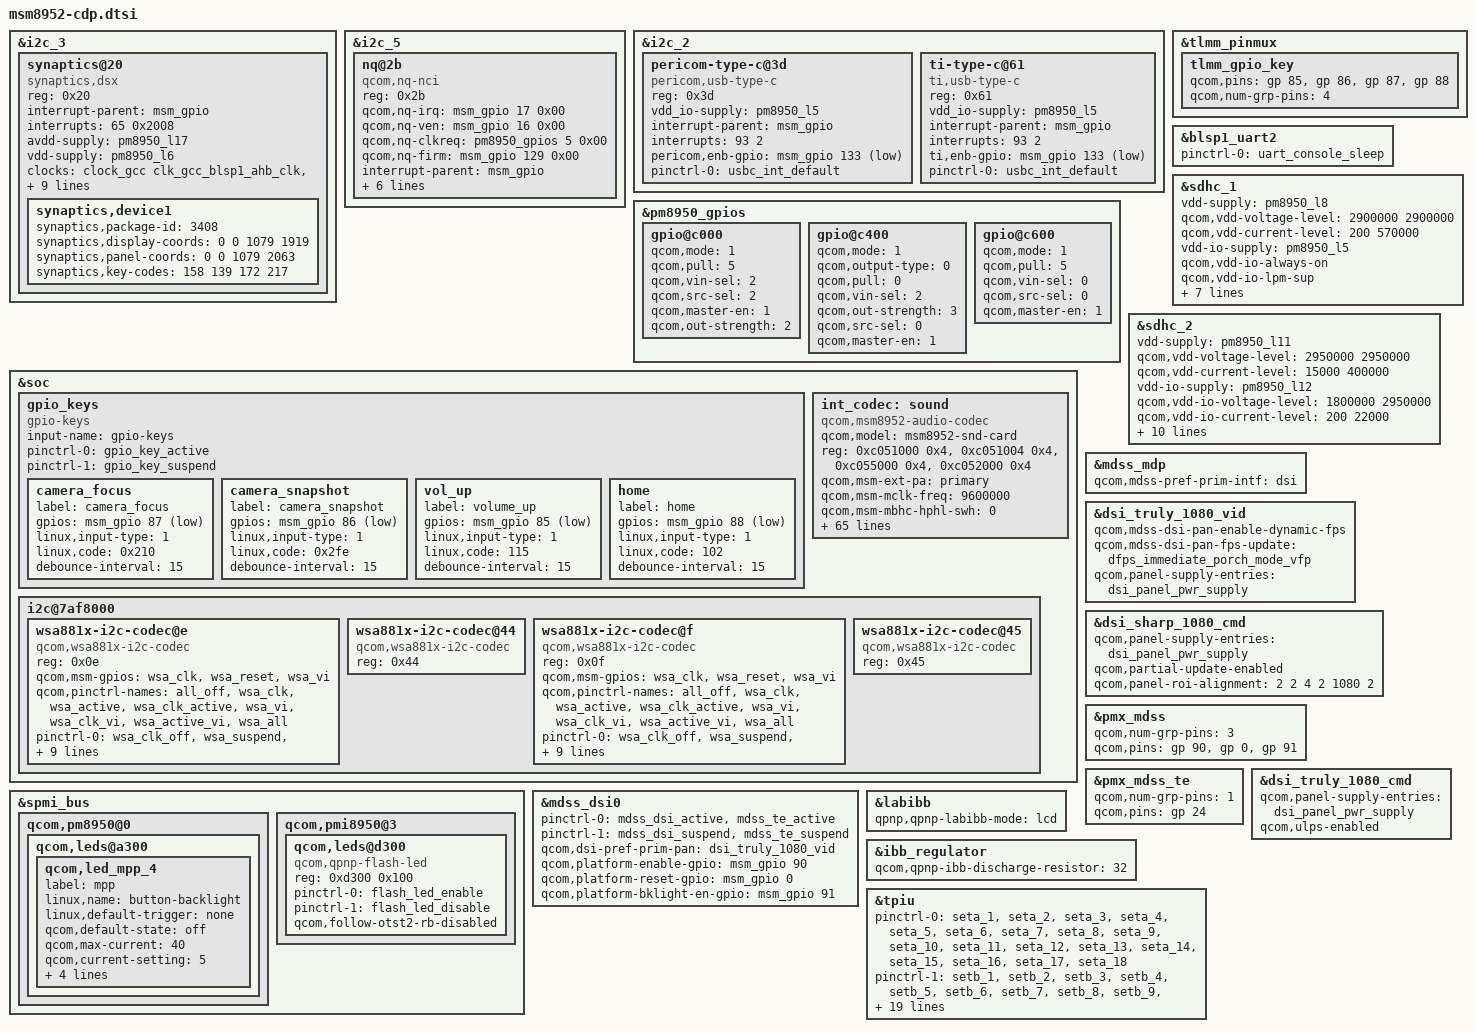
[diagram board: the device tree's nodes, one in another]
/*
 * Copyright (c) 2015, The Linux Foundation. All rights reserved.
 *
 * This program is free software; you can redistribute it and/or modify
 * it under the terms of the GNU General Public License version 2 and
 * only version 2 as published by the Free Software Foundation.
 *
 * This program is distributed in the hope that it will be useful,
 * but WITHOUT ANY WARRANTY; without even the implied warranty of
 * MERCHANTABILITY or FITNESS FOR A PARTICULAR PURPOSE.  See the
 * GNU General Public License for more details.
 */

#include "msm8952.dtsi"
#include "msm8952-pinctrl.dtsi"
#include "msm8952-camera-sensor-cdp.dtsi"

&i2c_3 { /* BLSP1 QUP3 */
	synaptics@20 {
		compatible = "synaptics,dsx";
		reg = <0x20>;
		interrupt-parent = <&msm_gpio>;
		interrupts = <65 0x2008>;
		avdd-supply = <&pm8950_l17>;
		vdd-supply = <&pm8950_l6>;
		clock-names = "iface_clk", "core_clk";
		clocks = <&clock_gcc clk_gcc_blsp1_ahb_clk>,
			<&clock_gcc clk_gcc_blsp1_qup3_i2c_apps_clk>;
		/* pins used by touchscreen */
		pinctrl-names = "pmx_ts_active","pmx_ts_suspend","pmx_ts_release";
		pinctrl-0 = <&ts_int_active &ts_reset_active>;
		pinctrl-1 = <&ts_int_suspend &ts_reset_suspend>;
		pinctrl-2 = <&ts_release>;
		synaptics,irq-gpio = <&msm_gpio 65 0x2008>;
		synaptics,reset-gpio = <&msm_gpio 64 0x0>;
		synaptics,disable-gpios;
		synaptics,detect-device;
		synaptics,bypass-packrat-id-check;
		synaptics,device1 {
			synaptics,package-id = <3408>;
			synaptics,display-coords = <0 0 1079 1919>;
			synaptics,panel-coords = <0 0 1079 2063>;
			synaptics,key-codes = <158 139 172 217>;
		};
	};
};

&i2c_5 { /* BLSP2 QUP1 */
	nq@2b {
		compatible = "qcom,nq-nci";
		reg = <0x2b>;
		qcom,nq-irq = <&msm_gpio 17 0x00>;
		qcom,nq-ven = <&msm_gpio 16 0x00>;
		qcom,nq-clkreq = <&pm8950_gpios 5 0x00>;
		qcom,nq-firm = <&msm_gpio 129 0x00>;
		interrupt-parent = <&msm_gpio>;
		qcom,clk-src = "BBCLK2";
		interrupts = <17 0>;
		interrupt-names = "nfc_irq";
		pinctrl-names = "nfc_active", "nfc_suspend";
		pinctrl-0 = <&nfc_int_active &nfc_disable_active>;
		pinctrl-1 = <&nfc_int_suspend &nfc_disable_suspend>;
		clocks = <&clock_gcc clk_bb_clk2_pin>;
		clock-names = "ref_clk";
	};
};

&i2c_2 {
	pericom-type-c@3d {
		compatible = "pericom,usb-type-c";
		reg = <0x3d>;
		vdd_io-supply = <&pm8950_l5>;
		interrupt-parent = <&msm_gpio>;
		interrupts = <93 2>;    /* MSM GPIO 93, TRIGGER_FALLING */
		pericom,enb-gpio = <&msm_gpio 133 0x1>;	/* active low ENB */
		pinctrl-names = "default";
		pinctrl-0 = <&usbc_int_default>;
	};

	ti-type-c@61 {
		compatible = "ti,usb-type-c";
		reg = <0x61>;
		vdd_io-supply = <&pm8950_l5>;
		interrupt-parent = <&msm_gpio>;
		interrupts = <93 2>;    /* MSM GPIO 93, TRIGGER_FALLING */
		ti,enb-gpio = <&msm_gpio 133 0x1>;	/* active low ENB */
		pinctrl-names = "default";
		pinctrl-0 = <&usbc_int_default>;
	};
};

&pm8950_gpios {
	gpio@c000 {
		status = "ok";
		qcom,mode = <1>;
		qcom,pull = <5>;
		qcom,vin-sel = <2>;
		qcom,src-sel = <2>;
		qcom,master-en = <1>;
		qcom,out-strength = <2>;
	};
	gpio@c400 {
		qcom,mode = <1>;
		qcom,output-type = <0>;
		qcom,pull = <0>;
		qcom,vin-sel = <2>;
		qcom,out-strength = <3>;
		qcom,src-sel = <0>;
		qcom,master-en = <1>;
		status = "okay";
	};
	gpio@c600 {
		status = "ok";
		qcom,mode = <1>;
		qcom,pull = <5>;
		qcom,vin-sel = <0>;
		qcom,src-sel = <0>;
		qcom,master-en = <1>;
	};
};

&soc {
	gpio_keys {
		compatible = "gpio-keys";
		input-name = "gpio-keys";
		pinctrl-names = "tlmm_gpio_key_active","tlmm_gpio_key_suspend";
		pinctrl-0 = <&gpio_key_active>;
		pinctrl-1 = <&gpio_key_suspend>;

		camera_focus {
			label = "camera_focus";
			gpios = <&msm_gpio 87 0x1>;
			linux,input-type = <1>;
			linux,code = <0x210>;
			debounce-interval = <15>;
		};

		camera_snapshot {
			label = "camera_snapshot";
			gpios = <&msm_gpio 86 0x1>;
			linux,input-type = <1>;
			linux,code = <0x2fe>;
			debounce-interval = <15>;
		};

		vol_up {
			label = "volume_up";
			gpios = <&msm_gpio 85 0x1>;
			linux,input-type = <1>;
			linux,code = <115>;
			debounce-interval = <15>;
		};

		home {
			label = "home";
			gpios = <&msm_gpio 88 0x1>;
			linux,input-type = <1>;
			linux,code = <102>;
			debounce-interval = <15>;
		};
	};

	int_codec: sound {
		compatible = "qcom,msm8952-audio-codec";
		qcom,model = "msm8952-snd-card";
		reg = <0xc051000 0x4>,
		      <0xc051004 0x4>,
		      <0xc055000 0x4>,
		      <0xc052000 0x4>;
		reg-names = "csr_gp_io_mux_mic_ctl",
			    "csr_gp_io_mux_spkr_ctl",
			    "csr_gp_io_lpaif_pri_pcm_pri_mode_muxsel",
			    "csr_gp_io_mux_quin_ctl";

		qcom,msm-ext-pa = "primary";
		qcom,msm-mclk-freq = <9600000>;
		qcom,msm-mbhc-hphl-swh = <0>;
		qcom,msm-mbhc-gnd-swh = <0>;
		qcom,msm-hs-micbias-type = "external";
		qcom,msm-micbias1-ext-cap;
		qcom,audio-routing =
			"RX_BIAS", "MCLK",
			"SPK_RX_BIAS", "MCLK",
			"INT_LDO_H", "MCLK",
			"MIC BIAS External", "Handset Mic",
			"MIC BIAS External2", "Headset Mic",
			"MIC BIAS External", "Secondary Mic",
			"AMIC1", "MIC BIAS External",
			"AMIC2", "MIC BIAS External2",
			"AMIC3", "MIC BIAS External",
			"WSA_SPK OUT", "VDD_WSA_SWITCH",
			"SpkrMono WSA_IN", "WSA_SPK OUT";
		qcom,msm-gpios =
			"pri_i2s",
			"us_eu_gpio";
		qcom,pinctrl-names =
			"all_off",
			"pri_i2s_act",
			"us_eu_gpio_act",
			"pri_i2s_us_eu_gpio_act";
		pinctrl-names =
			"all_off",
			"pri_i2s_act",
			"us_eu_gpio_act",
			"pri_i2s_us_eu_gpio_act";
		pinctrl-0 = <&cdc_pdm_lines_sus &cdc_pdm_lines_2_sus &cross_conn_det_sus>;
		pinctrl-1 = <&cdc_pdm_lines_act &cdc_pdm_lines_2_act &cross_conn_det_sus>;
		pinctrl-2 = <&cdc_pdm_lines_sus &cdc_pdm_lines_2_sus &cross_conn_det_act>;
		pinctrl-3 = <&cdc_pdm_lines_act &cdc_pdm_lines_2_act &cross_conn_det_act>;
		qcom,cdc-us-euro-gpios = <&msm_gpio 63 0>;
		asoc-platform = <&pcm0>, <&pcm1>, <&pcm2>, <&voip>, <&voice>,
				<&loopback>, <&compress>, <&hostless>,
				<&afe>, <&lsm>, <&routing>, <&lpa>,
				<&voice_svc>;
		asoc-platform-names = "msm-pcm-dsp.0", "msm-pcm-dsp.1", "msm-pcm-dsp.2",
				"msm-voip-dsp", "msm-pcm-voice", "msm-pcm-loopback",
				"msm-compress-dsp", "msm-pcm-hostless", "msm-pcm-afe",
				"msm-lsm-client", "msm-pcm-routing", "msm-pcm-lpa",
				"msm-voice-svc";
		asoc-cpu = <&dai_pri_auxpcm>, <&dai_hdmi>,
				<&dai_mi2s0>, <&dai_mi2s1>, <&dai_mi2s2>, <&dai_mi2s3>,
				<&dai_mi2s5>, <&dai_mi2s6>,
				<&sb_0_rx>, <&sb_0_tx>, <&sb_1_rx>, <&sb_1_tx>,
				<&sb_3_rx>, <&sb_3_tx>, <&sb_4_rx>, <&sb_4_tx>,
				<&bt_sco_rx>, <&bt_sco_tx>, <&int_fm_rx>, <&int_fm_tx>,
				<&afe_pcm_rx>, <&afe_pcm_tx>, <&afe_proxy_rx>, <&afe_proxy_tx>,
				<&incall_record_rx>, <&incall_record_tx>, <&incall_music_rx>,
				<&incall_music_2_rx>;
		asoc-cpu-names = "msm-dai-q6-auxpcm.1", "msm-dai-q6-hdmi.8",
				"msm-dai-q6-mi2s.0", "msm-dai-q6-mi2s.1",
				"msm-dai-q6-mi2s.2", "msm-dai-q6-mi2s.3",
				"msm-dai-q6-mi2s.5", "msm-dai-q6-mi2s.6",
				"msm-dai-q6-dev.16384", "msm-dai-q6-dev.16385",
				"msm-dai-q6-dev.16386", "msm-dai-q6-dev.16387",
				"msm-dai-q6-dev.16390", "msm-dai-q6-dev.16391",
				"msm-dai-q6-dev.16392", "msm-dai-q6-dev.16393",
				"msm-dai-q6-dev.12288", "msm-dai-q6-dev.12289",
				"msm-dai-q6-dev.12292", "msm-dai-q6-dev.12293",
				"msm-dai-q6-dev.224", "msm-dai-q6-dev.225",
				"msm-dai-q6-dev.241", "msm-dai-q6-dev.240",
				"msm-dai-q6-dev.32771", "msm-dai-q6-dev.32772",
				"msm-dai-q6-dev.32773", "msm-dai-q6-dev.32770";
		asoc-codec = <&stub_codec>, <&pm8950_cajon_dig>;
		asoc-codec-names = "msm-stub-codec.1", "cajon_codec";
		asoc-wsa-codec-names = "wsa881x-i2c-codec.8-000f";
		asoc-wsa-codec-prefixes = "SpkrMono";

		msm-vdd-wsa-switch-supply = <&pm8950_l13>;
		qcom,msm-vdd-wsa-switch-voltage = <3075000>;
		qcom,msm-vdd-wsa-switch-current = <5000>;
	};

	i2c@7af8000 {
		wsa881x-i2c-codec@e {
			compatible = "qcom,wsa881x-i2c-codec";
			reg = <0x0e>;
			qcom,msm-gpios = "wsa_clk",
					"wsa_reset",
					"wsa_vi";
			qcom,pinctrl-names = "all_off",
					"wsa_clk",
					"wsa_active",
					"wsa_clk_active",
					"wsa_vi",
					"wsa_clk_vi",
					"wsa_active_vi",
					"wsa_all";
			pinctrl-names = "all_off",
					"wsa_clk",
					"wsa_active",
					"wsa_clk_active",
					"wsa_vi",
					"wsa_clk_vi",
					"wsa_active_vi",
					"wsa_all";
			pinctrl-0 = <&wsa_clk_off &wsa_suspend &wsa_vi_sus>;
			pinctrl-1 = <&wsa_clk_on &wsa_suspend &wsa_vi_sus>;
			pinctrl-2 = <&wsa_clk_off &wsa_active &wsa_vi_sus>;
			pinctrl-3 = <&wsa_clk_on &wsa_active &wsa_vi_sus>;
			pinctrl-4 = <&wsa_clk_off &wsa_suspend &wsa_vi_act>;
			pinctrl-5 = <&wsa_clk_on &wsa_suspend &wsa_vi_act>;
			pinctrl-6 = <&wsa_clk_off &wsa_active &wsa_vi_act>;
			pinctrl-7 = <&wsa_clk_on &wsa_active &wsa_vi_act>;
		};
		wsa881x-i2c-codec@44 {
			compatible = "qcom,wsa881x-i2c-codec";
			reg = <0x44>;
		};
		wsa881x-i2c-codec@f {
			compatible = "qcom,wsa881x-i2c-codec";
			reg = <0x0f>;
			qcom,msm-gpios = "wsa_clk",
					"wsa_reset",
					"wsa_vi";
			qcom,pinctrl-names = "all_off",
					"wsa_clk",
					"wsa_active",
					"wsa_clk_active",
					"wsa_vi",
					"wsa_clk_vi",
					"wsa_active_vi",
					"wsa_all";
			pinctrl-names = "all_off",
					"wsa_clk",
					"wsa_active",
					"wsa_clk_active",
					"wsa_vi",
					"wsa_clk_vi",
					"wsa_active_vi",
					"wsa_all";
			pinctrl-0 = <&wsa_clk_off &wsa_suspend &wsa_vi_sus>;
			pinctrl-1 = <&wsa_clk_on &wsa_suspend &wsa_vi_sus>;
			pinctrl-2 = <&wsa_clk_off &wsa_active &wsa_vi_sus>;
			pinctrl-3 = <&wsa_clk_on &wsa_active &wsa_vi_sus>;
			pinctrl-4 = <&wsa_clk_off &wsa_suspend &wsa_vi_act>;
			pinctrl-5 = <&wsa_clk_on &wsa_suspend &wsa_vi_act>;
			pinctrl-6 = <&wsa_clk_off &wsa_active &wsa_vi_act>;
			pinctrl-7 = <&wsa_clk_on &wsa_active &wsa_vi_act>;
		};
		wsa881x-i2c-codec@45 {
			compatible = "qcom,wsa881x-i2c-codec";
			reg = <0x45>;
		};
	};
};

&tlmm_pinmux {
        tlmm_gpio_key {
                qcom,pins = <&gp 85>, <&gp 86>, <&gp 87>, <&gp 88>;
                qcom,num-grp-pins = <4>;
        };
};

&blsp1_uart2 {
	status = "ok";
	pinctrl-names = "default";
	pinctrl-0 = <&uart_console_sleep>;
};

&spmi_bus {
	qcom,pm8950@0 {
		qcom,leds@a300 {
			status = "okay";
			qcom,led_mpp_4 {
				label = "mpp";
				linux,name = "button-backlight";
				linux,default-trigger = "none";
				qcom,default-state = "off";
				qcom,max-current = <40>;
				qcom,current-setting = <5>;
				qcom,id = <6>;
				qcom,mode = "manual";
				qcom,source-sel = <1>;
				qcom,mode-ctrl = <0x60>;
			};
		};
	};

	qcom,pmi8950@3 {
		qcom,leds@d300 {
			compatible = "qcom,qpnp-flash-led";
			status = "okay";
			reg = <0xd300 0x100>;
			pinctrl-names = "flash_led_enable","flash_led_disable";
			pinctrl-0 = <&flash_led_enable>;
			pinctrl-1 = <&flash_led_disable>;
			qcom,follow-otst2-rb-disabled;
		};
	};
};

&sdhc_1 {
	vdd-supply = <&pm8950_l8>;
	qcom,vdd-voltage-level = <2900000 2900000>;
	qcom,vdd-current-level = <200 570000>;

	vdd-io-supply = <&pm8950_l5>;
	qcom,vdd-io-always-on;
	qcom,vdd-io-lpm-sup;
	qcom,vdd-io-voltage-level = <1800000 1800000>;
	qcom,vdd-io-current-level = <200 325000>;

	pinctrl-names = "active", "sleep";
	pinctrl-0 = <&sdc1_clk_on &sdc1_cmd_on &sdc1_data_on &sdc1_rclk_on>;
	pinctrl-1 = <&sdc1_clk_off &sdc1_cmd_off &sdc1_data_off &sdc1_rclk_off>;

	qcom,nonremovable;

	status = "ok";
};

&sdhc_2 {
	vdd-supply = <&pm8950_l11>;
	qcom,vdd-voltage-level = <2950000 2950000>;
	qcom,vdd-current-level = <15000 400000>;

	vdd-io-supply = <&pm8950_l12>;
	qcom,vdd-io-voltage-level = <1800000 2950000>;
	qcom,vdd-io-current-level = <200 22000>;

	pinctrl-names = "active", "sleep";
	pinctrl-0 = <&sdc2_clk_on &sdc2_cmd_on &sdc2_data_on &sdc2_cd_on>;
	pinctrl-1 = <&sdc2_clk_off &sdc2_cmd_off &sdc2_data_off &sdc2_cd_off>;

	#address-cells = <0>;
	interrupt-parent = <&sdhc_2>;
	interrupts = <0 1 2>;
	#interrupt-cells = <1>;
	interrupt-map-mask = <0xffffffff>;
	interrupt-map = <0 &intc 0 125 0
			1 &intc 0 221 0
			2 &msm_gpio 67 0>;
	interrupt-names = "hc_irq", "pwr_irq", "status_irq";
	cd-gpios = <&msm_gpio 67 0x1>;

	status = "ok";
};

&mdss_mdp {
	qcom,mdss-pref-prim-intf = "dsi";
};

&dsi_truly_1080_vid {
	qcom,mdss-dsi-pan-enable-dynamic-fps;
	qcom,mdss-dsi-pan-fps-update = "dfps_immediate_porch_mode_vfp";
	qcom,panel-supply-entries = <&dsi_panel_pwr_supply>;
};

&dsi_sharp_1080_cmd {
	qcom,panel-supply-entries = <&dsi_panel_pwr_supply>;
	qcom,partial-update-enabled;
	qcom,panel-roi-alignment = <2 2 4 2 1080 2>;
};

&pmx_mdss {
	qcom,num-grp-pins = <3>;
	qcom,pins = <&gp 90>, <&gp 0>, <&gp 91>;
};

&pmx_mdss_te {
	qcom,num-grp-pins = <1>;
	qcom,pins = <&gp 24>;
};

&mdss_dsi0 {
	pinctrl-names = "mdss_default", "mdss_sleep";
	pinctrl-0 = <&mdss_dsi_active &mdss_te_active>;
	pinctrl-1 = <&mdss_dsi_suspend &mdss_te_suspend>;
	qcom,dsi-pref-prim-pan = <&dsi_truly_1080_vid>;

	qcom,platform-enable-gpio = <&msm_gpio 90 0>;
	qcom,platform-reset-gpio = <&msm_gpio 0 0>;
	qcom,platform-bklight-en-gpio = <&msm_gpio 91 0>;
};

&dsi_truly_1080_cmd {
	qcom,panel-supply-entries = <&dsi_panel_pwr_supply>;
	qcom,ulps-enabled;
};

&labibb {
	status = "ok";
	qpnp,qpnp-labibb-mode = "lcd";
};

&ibb_regulator {
	qcom,qpnp-ibb-discharge-resistor = <32>;
};

/* CoreSight */
&tpiu {
	pinctrl-names = "seta-pctrl", "setb-pctrl", "sdcard", "trace",
			"swduart", "swdtrc", "jtag", "spmi";
	/* Mictor */
	pinctrl-0 = <&seta_1 &seta_2 &seta_3 &seta_4 &seta_5 &seta_6 &seta_7
		     &seta_8 &seta_9 &seta_10 &seta_11 &seta_12 &seta_13
		     &seta_14 &seta_15 &seta_16 &seta_17 &seta_18>;
	pinctrl-1 = <&setb_1 &setb_2 &setb_3 &setb_4 &setb_5 &setb_6 &setb_7
		     &setb_8 &setb_9 &setb_10 &setb_11 &setb_12 &setb_13
		     &setb_14 &setb_15 &setb_16 &setb_17 &setb_18>;
	/* NIDnT */
	pinctrl-2 = <&qdsd_clk_sdcard &qdsd_cmd_sdcard
		    &qdsd_data0_sdcard &qdsd_data1_sdcard
		    &qdsd_data2_sdcard &qdsd_data3_sdcard>;
	pinctrl-3 = <&qdsd_clk_trace &qdsd_cmd_trace
		    &qdsd_data0_trace &qdsd_data1_trace
		    &qdsd_data2_trace &qdsd_data3_trace>;
	pinctrl-4 = <&qdsd_cmd_swduart &qdsd_data0_swduart
		    &qdsd_data1_swduart &qdsd_data2_swduart
		    &qdsd_data3_swduart>;
	pinctrl-5 = <&qdsd_clk_swdtrc &qdsd_cmd_swdtrc
		    &qdsd_data0_swdtrc &qdsd_data1_swdtrc
		    &qdsd_data2_swdtrc &qdsd_data3_swdtrc>;
	pinctrl-6 = <&qdsd_cmd_jtag &qdsd_data0_jtag
		    &qdsd_data1_jtag &qdsd_data2_jtag
		    &qdsd_data3_jtag>;
	pinctrl-7 = <&qdsd_clk_spmi &qdsd_cmd_spmi
		    &qdsd_data0_spmi &qdsd_data3_spmi>;
};
